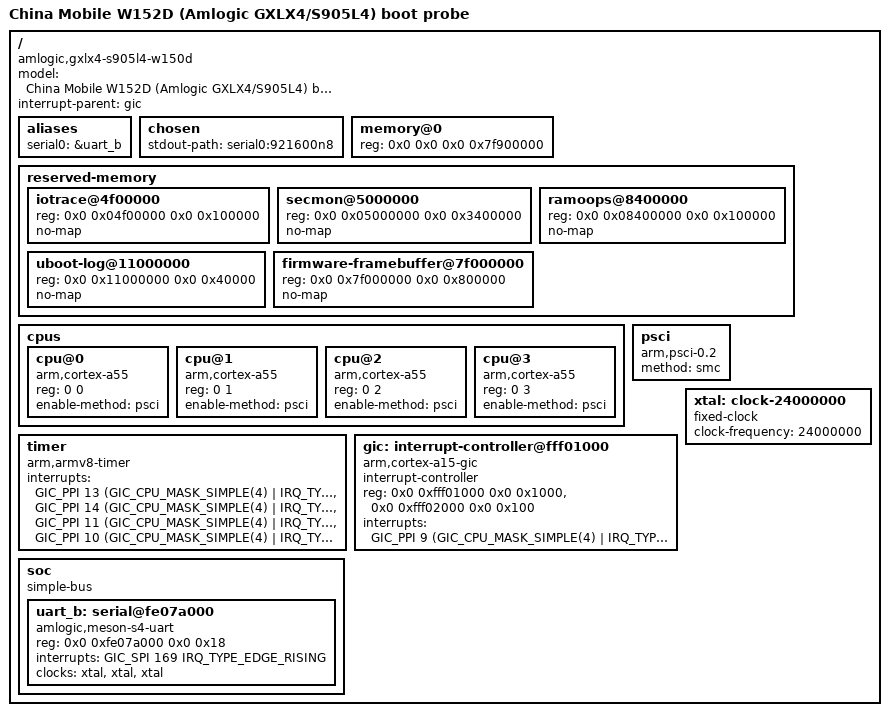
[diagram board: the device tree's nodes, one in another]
// SPDX-License-Identifier: GPL-2.0+
#ifndef W152D_BOOT_PROBE_DTS_INCLUDED
#define W152D_BOOT_PROBE_DTS_INCLUDED
/dts-v1/;

#include <dt-bindings/interrupt-controller/arm-gic.h>

/ {
	model = "China Mobile W152D (Amlogic GXLX4/S905L4) boot probe";
	compatible = "amlogic,gxlx4-s905l4-w150d", "amlogic,gxlx4";
	#address-cells = <2>;
	#size-cells = <2>;
	interrupt-parent = <&gic>;

	aliases {
		serial0 = &uart_b;
	};

	chosen {
		stdout-path = "serial0:921600n8";
	};

	/* Use the live stock FDT range after the firmware's RAM fixup. */
	memory@0 {
		device_type = "memory";
		reg = <0x0 0x0 0x0 0x7f900000>;
	};

	reserved-memory {
		#address-cells = <2>;
		#size-cells = <2>;
		ranges;

		/* Keep the existing firmware and diagnostic carveouts out of the allocator. */
		iotrace@4f00000 {
			reg = <0x0 0x04f00000 0x0 0x100000>;
			no-map;
		};

		secmon@5000000 {
			reg = <0x0 0x05000000 0x0 0x3400000>;
			no-map;
		};

		ramoops@8400000 {
			reg = <0x0 0x08400000 0x0 0x100000>;
			no-map;
		};

		uboot-log@11000000 {
			reg = <0x0 0x11000000 0x0 0x40000>;
			no-map;
		};

		firmware-framebuffer@7f000000 {
			reg = <0x0 0x7f000000 0x0 0x800000>;
			no-map;
		};
	};

	cpus {
		#address-cells = <2>;
		#size-cells = <0>;

		cpu@0 {
			device_type = "cpu";
			compatible = "arm,cortex-a55";
			reg = <0 0>;
			enable-method = "psci";
		};

		cpu@1 {
			device_type = "cpu";
			compatible = "arm,cortex-a55";
			reg = <0 1>;
			enable-method = "psci";
		};

		cpu@2 {
			device_type = "cpu";
			compatible = "arm,cortex-a55";
			reg = <0 2>;
			enable-method = "psci";
		};

		cpu@3 {
			device_type = "cpu";
			compatible = "arm,cortex-a55";
			reg = <0 3>;
			enable-method = "psci";
		};
	};

	psci {
		compatible = "arm,psci-0.2";
		method = "smc";
	};

	timer {
		compatible = "arm,armv8-timer";
		interrupts = <GIC_PPI 13 (GIC_CPU_MASK_SIMPLE(4) | IRQ_TYPE_LEVEL_LOW)>,
			     <GIC_PPI 14 (GIC_CPU_MASK_SIMPLE(4) | IRQ_TYPE_LEVEL_LOW)>,
			     <GIC_PPI 11 (GIC_CPU_MASK_SIMPLE(4) | IRQ_TYPE_LEVEL_LOW)>,
			     <GIC_PPI 10 (GIC_CPU_MASK_SIMPLE(4) | IRQ_TYPE_LEVEL_LOW)>;
	};

	/* Preserve the working vendor GIC window for initial IRQ/timer bring-up. */
	gic: interrupt-controller@fff01000 {
		compatible = "arm,cortex-a15-gic", "arm,cortex-a9-gic";
		#interrupt-cells = <3>;
		#address-cells = <0>;
		interrupt-controller;
		reg = <0x0 0xfff01000 0x0 0x1000>,
		      <0x0 0xfff02000 0x0 0x100>;
		interrupts = <GIC_PPI 9 (GIC_CPU_MASK_SIMPLE(4) | IRQ_TYPE_LEVEL_HIGH)>;
	};

	xtal: clock-24000000 {
		compatible = "fixed-clock";
		#clock-cells = <0>;
		clock-frequency = <24000000>;
	};

	soc {
		compatible = "simple-bus";
		#address-cells = <2>;
		#size-cells = <2>;
		ranges;

		uart_b: serial@fe07a000 {
			compatible = "amlogic,meson-s4-uart";
			reg = <0x0 0xfe07a000 0x0 0x18>;
			interrupts = <GIC_SPI 169 IRQ_TYPE_EDGE_RISING>;
			/* The pclk reference stands in for the firmware-enabled bus gate. */
			clocks = <&xtal>, <&xtal>, <&xtal>;
			clock-names = "xtal", "pclk", "baud";
		};
	};
};
#endif
